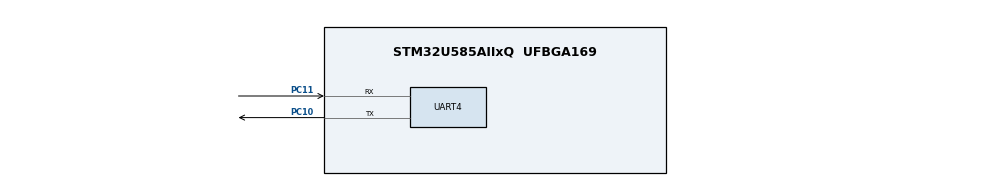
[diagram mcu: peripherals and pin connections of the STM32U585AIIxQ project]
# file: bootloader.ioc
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CORTEX_M33_NS.userName=CORTEX_M33
Mcu.Family=STM32U5
Mcu.Name=STM32U585AIIxQ
Mcu.Package=UFBGA169
NVIC.PriorityGroup=NVIC_PRIORITYGROUP_4
PC10.Mode=Asynchronous
PC10.Signal=UART4_TX
PC11.Mode=Asynchronous
PC11.Signal=UART4_RX
ProjectManager.HeapSize=0x200
ProjectManager.StackSize=0x400
ProjectManager.TargetToolchain=STM32CubeIDE
RCC.ADCFreq_Value=16000000
RCC.EPOD_VALUE=4000000
RCC.HSE_VALUE=16000000
RCC.HSI48_VALUE=48000000
RCC.HSI_VALUE=16000000
RCC.LSE_VALUE=32768
RCC.LSIDIV_VALUE=32000
RCC.MSI_VALUE=4000000
RCC.USBFreq_Value=48000000
RCC.VCOOutputFreq_Value=516000000
board=custom

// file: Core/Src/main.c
/* USER CODE BEGIN Header */
/**
  ******************************************************************************
  * @file           : main.c
  * @brief          : Main program body
  ******************************************************************************
  * @attention
  *
  * Copyright (c) 2024 STMicroelectronics.
  * All rights reserved.
  *
  * This software is licensed under terms that can be found in the LICENSE file
  * in the root directory of this software component.
  * If no LICENSE file comes with this software, it is provided AS-IS.
  *
  ******************************************************************************
  */
/* USER CODE END Header */
#include "main.h"

/* USER CODE BEGIN Includes */
#include <string.h>
#include <stdint.h>
#include <stdio.h>
/* USER CODE END Includes */

/* USER CODE BEGIN PTD */
typedef void (*pFunction)(void);
/* USER CODE END PTD */

/* USER CODE BEGIN PD */
#define FLASH_APP_ADDR 0x08008000
/* USER CODE END PD */

UART_HandleTypeDef huart4;

void SystemClock_Config(void);
static void MX_GPIO_Init(void);
static void MX_UART4_Init(void);

/* USER CODE BEGIN 0 */
// Override _write() function for printf
int _write(int file, char *ptr, int len) {
    HAL_UART_Transmit(&huart4, (uint8_t *)ptr, len, HAL_MAX_DELAY); // Transmit data via UART
    return len;
}

void go2App(void) {
	uint32_t JumpAddress;
	pFunction Jump_To_Application; //pFunction means pointer to a function
	printf("Bootloader Start\r\n");

	//jump to application
	JumpAddress = *(uint32_t*) (FLASH_APP_ADDR + 4); //where reset handler of the application is stored
	Jump_To_Application = (pFunction) JumpAddress;
	//initialize application’s stack pointer
	__set_MSP(*(__IO uint32_t*)FLASH_APP_ADDR);
	Jump_To_Application();
}

/* USER CODE END 0 */

int main(void)
{

  /* MCU Configuration--------------------------------------------------------*/

  /* Reset of all peripherals, Initializes the Flash interface and the Systick. */
  HAL_Init();

  /* Configure the system clock */
  SystemClock_Config();

  /* Initialize all configured peripherals */
  MX_GPIO_Init();
  MX_UART4_Init();

  /* Infinite loop */
  while (1)
  {
	  go2App();
  }
}

void SystemClock_Config(void)
{
  RCC_OscInitTypeDef RCC_OscInitStruct = {0};
  RCC_ClkInitTypeDef RCC_ClkInitStruct = {0};

  /** Configure the main internal regulator output voltage
  */
  if (HAL_PWREx_ControlVoltageScaling(PWR_REGULATOR_VOLTAGE_SCALE4) != HAL_OK)
  {
    Error_Handler();
  }

  /** Initializes the CPU, AHB and APB buses clocks
  */
  RCC_OscInitStruct.OscillatorType = RCC_OSCILLATORTYPE_MSI;
  RCC_OscInitStruct.MSIState = RCC_MSI_ON;
  RCC_OscInitStruct.MSICalibrationValue = RCC_MSICALIBRATION_DEFAULT;
  RCC_OscInitStruct.MSIClockRange = RCC_MSIRANGE_4;
  RCC_OscInitStruct.PLL.PLLState = RCC_PLL_NONE;
  if (HAL_RCC_OscConfig(&RCC_OscInitStruct) != HAL_OK)
  {
    Error_Handler();
  }

  /** Initializes the CPU, AHB and APB buses clocks
  */
  RCC_ClkInitStruct.ClockType = RCC_CLOCKTYPE_HCLK|RCC_CLOCKTYPE_SYSCLK
                              |RCC_CLOCKTYPE_PCLK1|RCC_CLOCKTYPE_PCLK2
                              |RCC_CLOCKTYPE_PCLK3;
  RCC_ClkInitStruct.SYSCLKSource = RCC_SYSCLKSOURCE_MSI;
  RCC_ClkInitStruct.AHBCLKDivider = RCC_SYSCLK_DIV1;
  RCC_ClkInitStruct.APB1CLKDivider = RCC_HCLK_DIV1;
  RCC_ClkInitStruct.APB2CLKDivider = RCC_HCLK_DIV1;
  RCC_ClkInitStruct.APB3CLKDivider = RCC_HCLK_DIV1;

  if (HAL_RCC_ClockConfig(&RCC_ClkInitStruct, FLASH_LATENCY_0) != HAL_OK)
  {
    Error_Handler();
  }
}

static void MX_UART4_Init(void)
{

  huart4.Instance = UART4;
  huart4.Init.BaudRate = 115200;
  huart4.Init.WordLength = UART_WORDLENGTH_8B;
  huart4.Init.StopBits = UART_STOPBITS_1;
  huart4.Init.Parity = UART_PARITY_NONE;
  huart4.Init.Mode = UART_MODE_TX_RX;
  huart4.Init.HwFlowCtl = UART_HWCONTROL_NONE;
  huart4.Init.OverSampling = UART_OVERSAMPLING_16;
  huart4.Init.OneBitSampling = UART_ONE_BIT_SAMPLE_DISABLE;
  huart4.Init.ClockPrescaler = UART_PRESCALER_DIV1;
  huart4.AdvancedInit.AdvFeatureInit = UART_ADVFEATURE_NO_INIT;
  if (HAL_UART_Init(&huart4) != HAL_OK)
  {
    Error_Handler();
  }
  if (HAL_UARTEx_SetTxFifoThreshold(&huart4, UART_TXFIFO_THRESHOLD_1_8) != HAL_OK)
  {
    Error_Handler();
  }
  if (HAL_UARTEx_SetRxFifoThreshold(&huart4, UART_RXFIFO_THRESHOLD_1_8) != HAL_OK)
  {
    Error_Handler();
  }
  if (HAL_UARTEx_DisableFifoMode(&huart4) != HAL_OK)
  {
    Error_Handler();
  }

}

static void MX_GPIO_Init(void)
{

  /* GPIO Ports Clock Enable */
  __HAL_RCC_GPIOC_CLK_ENABLE();

}

void Error_Handler(void)
{
  __disable_irq();
  while (1)
  {
  }
}
